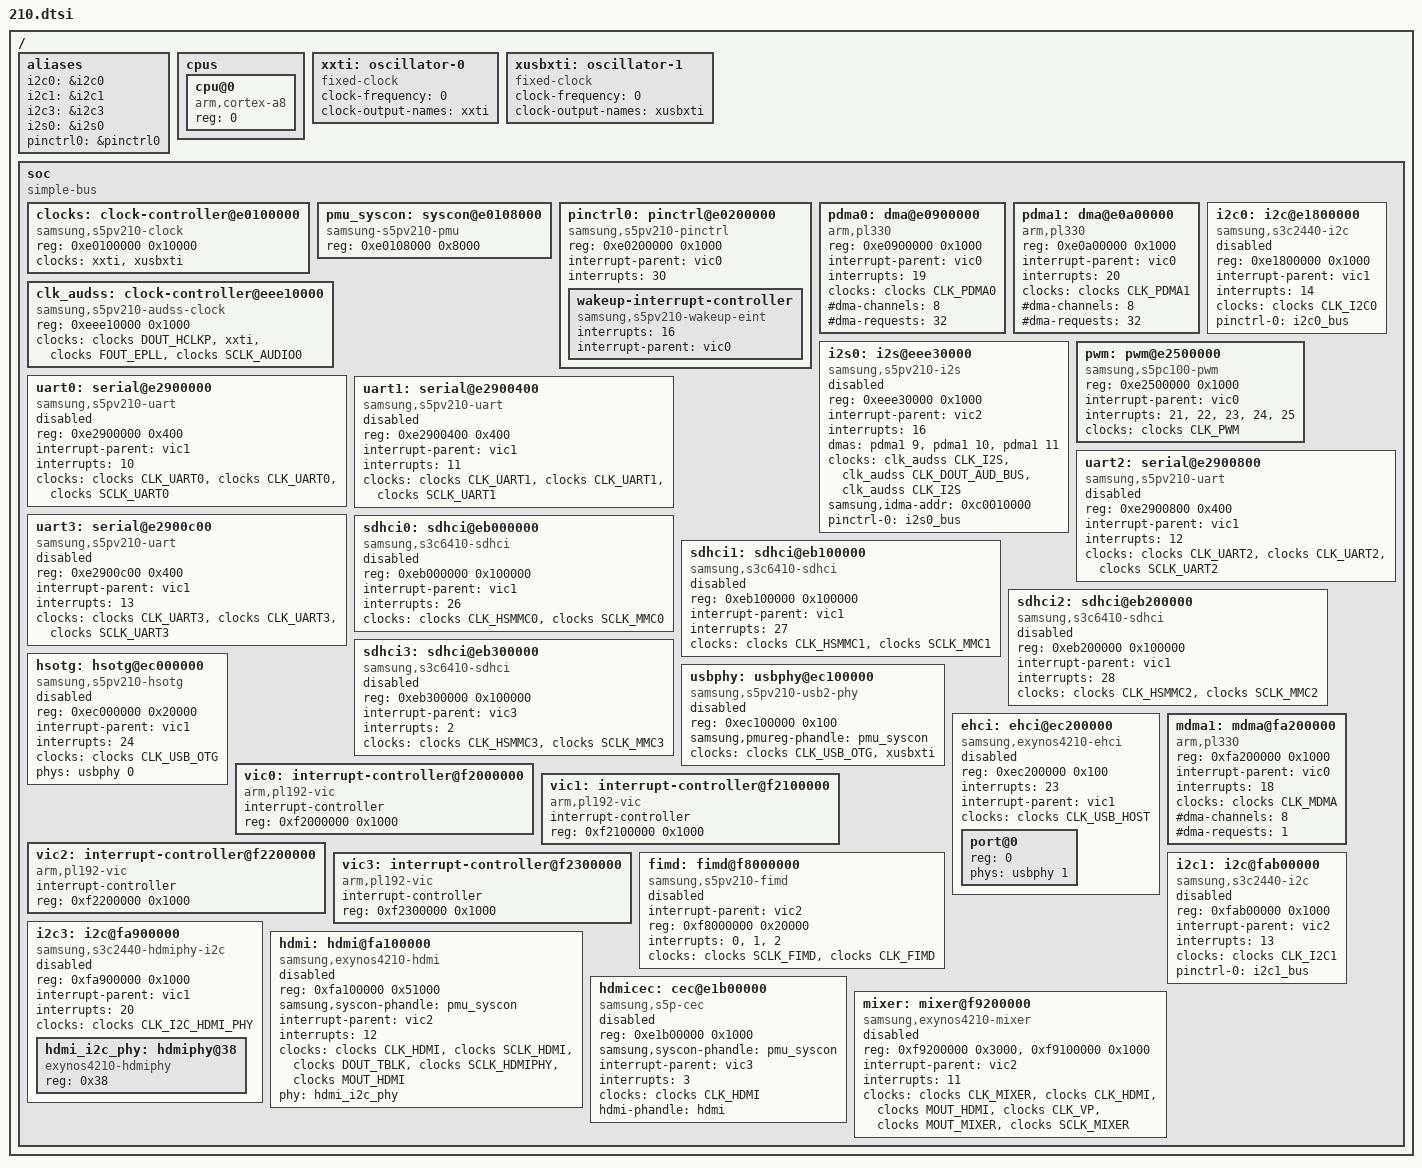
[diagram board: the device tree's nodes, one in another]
// SPDX-License-Identifier: GPL-2.0
/*
 * Samsung's S5PV210 SoC device tree source
 *
 * Copyright (c) 2013-2014 Samsung Electronics, Co. Ltd.
 *
 * Mateusz Krawczuk <m.krawczuk@partner.samsung.com>
 * Tomasz Figa <t.figa@samsung.com>
 *
 * Samsung's S5PV210 SoC device nodes are listed in this file. S5PV210
 * based board files can include this file and provide values for board specfic
 * bindings.
 *
 * Note: This file does not include device nodes for all the controllers in
 * S5PV210 SoC. As device tree coverage for S5PV210 increases, additional
 * nodes can be added to this file.
 */

#include <dt-bindings/clock/s5pv210.h>
#include <dt-bindings/clock/s5pv210-audss.h>

/ {
	#address-cells = <1>;
	#size-cells = <1>;

	aliases {
		i2c0 = &i2c0;
		i2c1 = &i2c1;
		i2c3 = &i2c3;
		i2s0 = &i2s0;
		pinctrl0 = &pinctrl0;
	};

	cpus {
		#address-cells = <1>;
		#size-cells = <0>;

		cpu@0 {
			device_type = "cpu";
			compatible = "arm,cortex-a8";
			reg = <0>;
		};
	};

	xxti: oscillator-0 {
		compatible = "fixed-clock";
		clock-frequency = <0>;
		clock-output-names = "xxti";
		#clock-cells = <0>;
	};

	xusbxti: oscillator-1 {
		compatible = "fixed-clock";
		clock-frequency = <0>;
		clock-output-names = "xusbxti";
		#clock-cells = <0>;
	};

	soc {
		compatible = "simple-bus";
		#address-cells = <1>;
		#size-cells = <1>;
		ranges;

		clocks: clock-controller@e0100000 {
			compatible = "samsung,s5pv210-clock";
			reg = <0xe0100000 0x10000>;
			clock-names = "xxti", "xusbxti";
			clocks = <&xxti>, <&xusbxti>;
			#clock-cells = <1>;
		};

		pmu_syscon: syscon@e0108000 {
			compatible = "samsung-s5pv210-pmu", "syscon";
			reg = <0xe0108000 0x8000>;
		};

		pinctrl0: pinctrl@e0200000 {
			compatible = "samsung,s5pv210-pinctrl";
			reg = <0xe0200000 0x1000>;
			interrupt-parent = <&vic0>;
			interrupts = <30>;

			wakeup-interrupt-controller {
				compatible = "samsung,s5pv210-wakeup-eint";
				interrupts = <16>;
				interrupt-parent = <&vic0>;
			};
		};

		pdma0: dma@e0900000 {
			compatible = "arm,pl330", "arm,primecell";
			reg = <0xe0900000 0x1000>;
			interrupt-parent = <&vic0>;
			interrupts = <19>;
			clocks = <&clocks CLK_PDMA0>;
			clock-names = "apb_pclk";
			#dma-cells = <1>;
			#dma-channels = <8>;
			#dma-requests = <32>;
		};

		pdma1: dma@e0a00000 {
			compatible = "arm,pl330", "arm,primecell";
			reg = <0xe0a00000 0x1000>;
			interrupt-parent = <&vic0>;
			interrupts = <20>;
			clocks = <&clocks CLK_PDMA1>;
			clock-names = "apb_pclk";
			#dma-cells = <1>;
			#dma-channels = <8>;
			#dma-requests = <32>;
		};

		i2c0: i2c@e1800000 {
			compatible = "samsung,s3c2440-i2c";
			reg = <0xe1800000 0x1000>;
			interrupt-parent = <&vic1>;
			interrupts = <14>;
			clocks = <&clocks CLK_I2C0>;
			clock-names = "i2c";
			pinctrl-names = "default";
			pinctrl-0 = <&i2c0_bus>;
			#address-cells = <1>;
			#size-cells = <0>;
			status = "disabled";
		};

		clk_audss: clock-controller@eee10000 {
			compatible = "samsung,s5pv210-audss-clock";
			reg = <0xeee10000 0x1000>;
			clock-names = "hclk", "xxti",
				      "fout_epll",
				      "sclk_audio0";
			clocks = <&clocks DOUT_HCLKP>, <&xxti>,
				 <&clocks FOUT_EPLL>,
				 <&clocks SCLK_AUDIO0>;
			#clock-cells = <1>;
		};

		i2s0: i2s@eee30000 {
			compatible = "samsung,s5pv210-i2s";
			reg = <0xeee30000 0x1000>;
			interrupt-parent = <&vic2>;
			interrupts = <16>;
			dma-names = "rx", "tx", "tx-sec";
			dmas = <&pdma1 9>, <&pdma1 10>, <&pdma1 11>;
			clock-names = "iis",
				      "i2s_opclk0",
				      "i2s_opclk1";
			clocks = <&clk_audss CLK_I2S>,
				 <&clk_audss CLK_DOUT_AUD_BUS>,
				 <&clk_audss CLK_I2S>;
			samsung,idma-addr = <0xc0010000>;
			pinctrl-names = "default";
			pinctrl-0 = <&i2s0_bus>;
			#sound-dai-cells = <0>;
			status = "disabled";
		};

		pwm: pwm@e2500000 {
			compatible = "samsung,s5pc100-pwm";
			reg = <0xe2500000 0x1000>;
			interrupt-parent = <&vic0>;
			interrupts = <21>, <22>, <23>, <24>, <25>;
			clock-names = "timers";
			clocks = <&clocks CLK_PWM>;
			#pwm-cells = <3>;
		};

		uart0: serial@e2900000 {
			compatible = "samsung,s5pv210-uart";
			reg = <0xe2900000 0x400>;
			interrupt-parent = <&vic1>;
			interrupts = <10>;
			clock-names = "uart", "clk_uart_baud0",
					"clk_uart_baud1";
			clocks = <&clocks CLK_UART0>, <&clocks CLK_UART0>,
					<&clocks SCLK_UART0>;
			status = "disabled";
		};

		uart1: serial@e2900400 {
			compatible = "samsung,s5pv210-uart";
			reg = <0xe2900400 0x400>;
			interrupt-parent = <&vic1>;
			interrupts = <11>;
			clock-names = "uart", "clk_uart_baud0",
					"clk_uart_baud1";
			clocks = <&clocks CLK_UART1>, <&clocks CLK_UART1>,
					<&clocks SCLK_UART1>;
			status = "disabled";
		};

		uart2: serial@e2900800 {
			compatible = "samsung,s5pv210-uart";
			reg = <0xe2900800 0x400>;
			interrupt-parent = <&vic1>;
			interrupts = <12>;
			clock-names = "uart", "clk_uart_baud0",
					"clk_uart_baud1";
			clocks = <&clocks CLK_UART2>, <&clocks CLK_UART2>,
					<&clocks SCLK_UART2>;
			status = "disabled";
		};

		uart3: serial@e2900c00 {
			compatible = "samsung,s5pv210-uart";
			reg = <0xe2900c00 0x400>;
			interrupt-parent = <&vic1>;
			interrupts = <13>;
			clock-names = "uart", "clk_uart_baud0",
					"clk_uart_baud1";
			clocks = <&clocks CLK_UART3>, <&clocks CLK_UART3>,
					<&clocks SCLK_UART3>;
			status = "disabled";
		};

		sdhci0: sdhci@eb000000 {
			compatible = "samsung,s3c6410-sdhci";
			reg = <0xeb000000 0x100000>;
			interrupt-parent = <&vic1>;
			interrupts = <26>;
			clock-names = "hsmmc", "mmc_busclk.0";
			clocks = <&clocks CLK_HSMMC0>,
					<&clocks SCLK_MMC0>;
			status = "disabled";
		};

		sdhci1: sdhci@eb100000 {
			compatible = "samsung,s3c6410-sdhci";
			reg = <0xeb100000 0x100000>;
			interrupt-parent = <&vic1>;
			interrupts = <27>;
			clock-names = "hsmmc", "mmc_busclk.0";
			clocks = <&clocks CLK_HSMMC1>,
					<&clocks SCLK_MMC1>;
			status = "disabled";
		};

		sdhci2: sdhci@eb200000 {
			compatible = "samsung,s3c6410-sdhci";
			reg = <0xeb200000 0x100000>;
			interrupt-parent = <&vic1>;
			interrupts = <28>;
			clock-names = "hsmmc", "mmc_busclk.0";
			clocks = <&clocks CLK_HSMMC2>,
					<&clocks SCLK_MMC2>;
			status = "disabled";
		};

		sdhci3: sdhci@eb300000 {
			compatible = "samsung,s3c6410-sdhci";
			reg = <0xeb300000 0x100000>;
			interrupt-parent = <&vic3>;
			interrupts = <2>;
			clock-names = "hsmmc", "mmc_busclk.0";
			clocks = <&clocks CLK_HSMMC3>,
					<&clocks SCLK_MMC3>;
			status = "disabled";
		};

		hsotg: hsotg@ec000000 {
			compatible = "samsung,s5pv210-hsotg";
			reg = <0xec000000 0x20000>;
			interrupt-parent = <&vic1>;
			interrupts = <24>;
			clocks = <&clocks CLK_USB_OTG>;
			clock-names = "otg";
			phy-names = "usb2-phy";
			phys = <&usbphy 0>;
			status = "disabled";
		};

		usbphy: usbphy@ec100000 {
			compatible = "samsung,s5pv210-usb2-phy";
			reg = <0xec100000 0x100>;
			samsung,pmureg-phandle = <&pmu_syscon>;
			clocks = <&clocks CLK_USB_OTG>, <&xusbxti>;
			clock-names = "phy", "ref";
			#phy-cells = <1>;
			status = "disabled";
		};

		ehci: ehci@ec200000 {
			compatible = "samsung,exynos4210-ehci";
			reg = <0xec200000 0x100>;
			interrupts = <23>;
			interrupt-parent = <&vic1>;
			clocks = <&clocks CLK_USB_HOST>;
			clock-names = "usbhost";
			#address-cells = <1>;
			#size-cells = <0>;
			status = "disabled";

			port@0 {
				reg = <0>;
				phys = <&usbphy 1>;
			};
		};

		vic0: interrupt-controller@f2000000 {
			compatible = "arm,pl192-vic";
			interrupt-controller;
			reg = <0xf2000000 0x1000>;
			#interrupt-cells = <1>;
		};

		vic1: interrupt-controller@f2100000 {
			compatible = "arm,pl192-vic";
			interrupt-controller;
			reg = <0xf2100000 0x1000>;
			#interrupt-cells = <1>;
		};

		vic2: interrupt-controller@f2200000 {
			compatible = "arm,pl192-vic";
			interrupt-controller;
			reg = <0xf2200000 0x1000>;
			#interrupt-cells = <1>;
		};

		vic3: interrupt-controller@f2300000 {
			compatible = "arm,pl192-vic";
			interrupt-controller;
			reg = <0xf2300000 0x1000>;
			#interrupt-cells = <1>;
		};

		fimd: fimd@f8000000 {
			compatible = "samsung,s5pv210-fimd";
			interrupt-parent = <&vic2>;
			reg = <0xf8000000 0x20000>;
			interrupt-names = "fifo", "vsync", "lcd_sys";
			interrupts = <0>, <1>, <2>;
			clocks = <&clocks SCLK_FIMD>, <&clocks CLK_FIMD>;
			clock-names = "sclk_fimd", "fimd";
			status = "disabled";
		};

		mdma1: mdma@fa200000 {
			compatible = "arm,pl330", "arm,primecell";
			reg = <0xfa200000 0x1000>;
			interrupt-parent = <&vic0>;
			interrupts = <18>;
			clocks = <&clocks CLK_MDMA>;
			clock-names = "apb_pclk";
			#dma-cells = <1>;
			#dma-channels = <8>;
			#dma-requests = <1>;
		};

		i2c1: i2c@fab00000 {
			compatible = "samsung,s3c2440-i2c";
			reg = <0xfab00000 0x1000>;
			interrupt-parent = <&vic2>;
			interrupts = <13>;
			clocks = <&clocks CLK_I2C1>;
			clock-names = "i2c";
			pinctrl-names = "default";
			pinctrl-0 = <&i2c1_bus>;
			#address-cells = <1>;
			#size-cells = <0>;
			status = "disabled";
		};

		i2c3: i2c@fa900000 {
			compatible = "samsung,s3c2440-hdmiphy-i2c";
			reg = <0xfa900000 0x1000>;
			interrupt-parent = <&vic1>;
			interrupts = <20>;
			clocks = <&clocks CLK_I2C_HDMI_PHY>;
			clock-names = "i2c";
			#address-cells = <1>;
			#size-cells = <0>;
			status = "disabled";

			hdmi_i2c_phy: hdmiphy@38 {
				compatible = "exynos4210-hdmiphy";
				reg = <0x38>;
			};
		};

		hdmi: hdmi@fa100000 {
			compatible = "samsung,exynos4210-hdmi";
			reg = <0xfa100000 0x51000>;
			samsung,syscon-phandle = <&pmu_syscon>;
			interrupt-parent = <&vic2>;
			interrupts = <12>;
			clocks = <&clocks CLK_HDMI>, <&clocks SCLK_HDMI>,
				 <&clocks DOUT_TBLK>,
				 <&clocks SCLK_HDMIPHY>,
				 <&clocks MOUT_HDMI>;
			clock-names = "hdmi", "sclk_hdmi", "sclk_pixel",
				      "sclk_hdmiphy", "mout_hdmi";
			phy = <&hdmi_i2c_phy>;
			#sound-dai-cells = <0>;
			status = "disabled";
		};

		hdmicec: cec@e1b00000 {
			compatible = "samsung,s5p-cec";
			reg = <0xe1b00000 0x1000>;
			samsung,syscon-phandle = <&pmu_syscon>;
			interrupt-parent = <&vic3>;
			interrupts = <3>;
			clocks = <&clocks CLK_HDMI>;
			clock-names = "hdmicec";
			hdmi-phandle = <&hdmi>;
			status = "disabled";
		};

		mixer: mixer@f9200000 {
			compatible = "samsung,exynos4210-mixer";
			reg = <0xf9200000 0x3000>, <0xf9100000 0x1000>;
			interrupt-parent = <&vic2>;
			interrupts = <11>;
			clocks = <&clocks CLK_MIXER>, <&clocks CLK_HDMI>,
				 <&clocks MOUT_HDMI>, <&clocks CLK_VP>,
				 <&clocks MOUT_MIXER>, <&clocks SCLK_MIXER>;
			clock-names = "mixer", "hdmi", "mout_hdmi", "vp", "mout_mixer",
					  "sclk_mixer";
			status = "disabled";
		};
	};
};

#include "210-pinctrl.dtsi"
